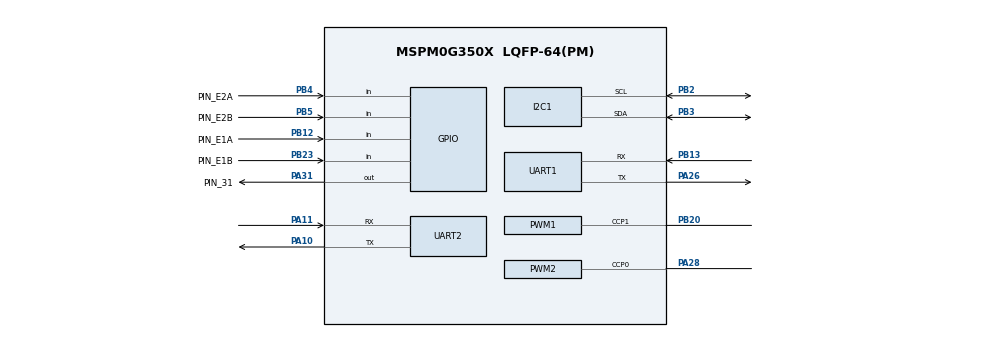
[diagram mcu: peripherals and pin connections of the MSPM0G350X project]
/**
 * @cliArgs --device "MSPM0G350X" --part "Default" --package "LQFP-64(PM)" --product "mspm0_sdk@2.10.00.04"
 * @versions {"tool":"1.27.1+4634"}
 */

/**
 * Import the modules used in this configuration.
 */
const ADC12         = scripting.addModule("/ti/driverlib/ADC12", {}, false);
const ADC121        = ADC12.addInstance();
const Board         = scripting.addModule("/ti/driverlib/Board");
const GPIO          = scripting.addModule("/ti/driverlib/GPIO", {}, false);
const GPIO1         = GPIO.addInstance();
const GPIO2         = GPIO.addInstance();
const GPIO3         = GPIO.addInstance();
const GPIO4         = GPIO.addInstance();
const GPIO5         = GPIO.addInstance();
const GPIO6         = GPIO.addInstance();
const GPIO7         = GPIO.addInstance();
const GPIO8         = GPIO.addInstance();
const GPIO9         = GPIO.addInstance();
const GPIO10        = GPIO.addInstance();
const GPIO11        = GPIO.addInstance();
const GPIO12        = GPIO.addInstance();
const GPIO13        = GPIO.addInstance();
const I2C           = scripting.addModule("/ti/driverlib/I2C", {}, false);
const I2C1          = I2C.addInstance();
const MATHACL       = scripting.addModule("/ti/driverlib/MATHACL");
const PWM           = scripting.addModule("/ti/driverlib/PWM", {}, false);
const PWM1          = PWM.addInstance();
const PWM2          = PWM.addInstance();
const SYSCTL        = scripting.addModule("/ti/driverlib/SYSCTL");
const UART          = scripting.addModule("/ti/driverlib/UART", {}, false);
const UART1         = UART.addInstance();
const UART2         = UART.addInstance();
const ProjectConfig = scripting.addModule("/ti/project_config/ProjectConfig");

/**
 * Write custom configuration values to the imported modules.
 */
const divider9       = system.clockTree["UDIV"];
divider9.divideValue = 2;

const gate7  = system.clockTree["MFCLKGATE"];
gate7.enable = true;

const mux4       = system.clockTree["EXHFMUX"];
mux4.inputSelect = "EXHFMUX_XTAL";

const mux5       = system.clockTree["EXLFMUX"];
mux5.inputSelect = "EXLFMUX_XTAL";

const mux8       = system.clockTree["HSCLKMUX"];
mux8.inputSelect = "HSCLKMUX_SYSPLL2X";

const mux12       = system.clockTree["SYSPLLMUX"];
mux12.inputSelect = "zSYSPLLMUX_HFCLK";

const pinFunction4     = system.clockTree["HFXT"];
pinFunction4.enable    = true;
pinFunction4.inputFreq = 40;

const pinFunction6     = system.clockTree["LFXT"];
pinFunction6.enable    = true;
pinFunction6.inputFreq = 32.768;

ADC121.$name                      = "ADC12_0";
ADC121.configureDMA               = true;
ADC121.enabledDMATriggers         = ["DL_ADC12_DMA_MEM0_RESULT_LOADED"];
ADC121.sampCnt                    = 1;
ADC121.repeatMode                 = true;
ADC121.sampleTime0                = "0.5 ms";
ADC121.peripheral.adcPin0.$assign = "PA27";
ADC121.adcPin0Config.$name        = "ti_driverlib_gpio_GPIOPinGeneric4";
ADC121.DMA_CHANNEL.$name          = "DMA_CH0";
ADC121.DMA_CHANNEL.transferMode   = "FULL_CH_REPEAT_SINGLE";
ADC121.DMA_CHANNEL.srcLength      = "HALF_WORD";
ADC121.DMA_CHANNEL.dstLength      = "HALF_WORD";


GPIO1.port                          = "PORTB";
GPIO1.$name                         = "LED1";
GPIO1.associatedPins[0].$name       = "PIN_22";
GPIO1.associatedPins[0].assignedPin = "22";

GPIO2.$name                         = "AD0";
GPIO2.port                          = "PORTA";
GPIO2.associatedPins[0].$name       = "PIN_31";
GPIO2.associatedPins[0].assignedPin = "31";
GPIO2.associatedPins[0].pin.$assign = "PA31";

GPIO3.$name                   = "AD1";
GPIO3.port                    = "PORTA";
GPIO3.associatedPins[0].$name = "PIN_12";

GPIO4.$name                         = "AD2";
GPIO4.port                          = "PORTB";
GPIO4.associatedPins[0].$name       = "PIN_8";
GPIO4.associatedPins[0].assignedPin = "8";

GPIO5.$name                         = "EN";
GPIO5.port                          = "PORTB";
GPIO5.associatedPins[0].$name       = "PIN_27";
GPIO5.associatedPins[0].assignedPin = "27";

GPIO6.$name                         = "AIN1";
GPIO6.port                          = "PORTA";
GPIO6.associatedPins[0].$name       = "PIN_13";
GPIO6.associatedPins[0].assignedPin = "13";

GPIO7.$name                         = "AIN2";
GPIO7.port                          = "PORTB";
GPIO7.associatedPins[0].$name       = "PIN_26";
GPIO7.associatedPins[0].assignedPin = "26";

GPIO8.$name                         = "BIN1";
GPIO8.port                          = "PORTB";
GPIO8.associatedPins[0].$name       = "PIN_9";
GPIO8.associatedPins[0].assignedPin = "9";

GPIO9.$name                         = "BIN2";
GPIO9.port                          = "PORTB";
GPIO9.associatedPins[0].$name       = "PIN_7";
GPIO9.associatedPins[0].assignedPin = "7";

GPIO10.$name                              = "E1A";
GPIO10.port                               = "PORTB";
GPIO10.associatedPins[0].$name            = "PIN_E1A";
GPIO10.associatedPins[0].direction        = "INPUT";
GPIO10.associatedPins[0].internalResistor = "PULL_UP";
GPIO10.associatedPins[0].interruptEn      = true;
GPIO10.associatedPins[0].polarity         = "RISE_FALL";
GPIO10.associatedPins[0].pin.$assign      = "PB12";

GPIO11.$name                              = "E1B";
GPIO11.port                               = "PORTB";
GPIO11.associatedPins[0].$name            = "PIN_E1B";
GPIO11.associatedPins[0].direction        = "INPUT";
GPIO11.associatedPins[0].internalResistor = "PULL_UP";
GPIO11.associatedPins[0].interruptEn      = true;
GPIO11.associatedPins[0].polarity         = "RISE_FALL";
GPIO11.associatedPins[0].pin.$assign      = "PB23";

GPIO12.$name                              = "E2A";
GPIO12.port                               = "PORTB";
GPIO12.associatedPins[0].$name            = "PIN_E2A";
GPIO12.associatedPins[0].direction        = "INPUT";
GPIO12.associatedPins[0].internalResistor = "PULL_UP";
GPIO12.associatedPins[0].interruptEn      = true;
GPIO12.associatedPins[0].polarity         = "RISE_FALL";
GPIO12.associatedPins[0].pin.$assign      = "PB4";

GPIO13.$name                              = "E2B";
GPIO13.port                               = "PORTB";
GPIO13.associatedPins[0].$name            = "PIN_E2B";
GPIO13.associatedPins[0].direction        = "INPUT";
GPIO13.associatedPins[0].internalResistor = "PULL_UP";
GPIO13.associatedPins[0].interruptEn      = true;
GPIO13.associatedPins[0].polarity         = "RISE_FALL";
GPIO13.associatedPins[0].pin.$assign      = "PB5";

I2C1.$name                             = "OLED";
I2C1.basicEnableController             = true;
I2C1.basicControllerBusSpeed           = 400000;
I2C1.peripheral.sdaPin.$assign         = "PB3";
I2C1.peripheral.sclPin.$assign         = "PB2";
I2C1.sdaPinConfig.hideOutputInversion  = scripting.forceWrite(false);
I2C1.sdaPinConfig.onlyInternalResistor = scripting.forceWrite(false);
I2C1.sdaPinConfig.passedPeripheralType = scripting.forceWrite("Digital");
I2C1.sdaPinConfig.$name                = "ti_driverlib_gpio_GPIOPinGeneric5";
I2C1.sclPinConfig.hideOutputInversion  = scripting.forceWrite(false);
I2C1.sclPinConfig.onlyInternalResistor = scripting.forceWrite(false);
I2C1.sclPinConfig.passedPeripheralType = scripting.forceWrite("Digital");
I2C1.sclPinConfig.$name                = "ti_driverlib_gpio_GPIOPinGeneric6";

PWM1.pwmMode                                 = "EDGE_ALIGN_UP";
PWM1.ccIndexCmpl                             = [0];
PWM1.$name                                   = "PWMB";
PWM1.PWM_CHANNEL_0.$name                     = "ti_driverlib_pwm_PWMTimerCC0";
PWM1.PWM_CHANNEL_1.$name                     = "ti_driverlib_pwm_PWMTimerCC1";
PWM1.ccp0PinConfig.direction                 = scripting.forceWrite("OUTPUT");
PWM1.ccp0PinConfig.hideOutputInversion       = scripting.forceWrite(false);
PWM1.ccp0PinConfig.onlyInternalResistor      = scripting.forceWrite(false);
PWM1.ccp0PinConfig.passedPeripheralType      = scripting.forceWrite("Digital");
PWM1.ccp0PinConfig.$name                     = "ti_driverlib_gpio_GPIOPinGeneric7";
PWM1.ccp1PinConfig.direction                 = scripting.forceWrite("OUTPUT");
PWM1.ccp1PinConfig.hideOutputInversion       = scripting.forceWrite(false);
PWM1.ccp1PinConfig.onlyInternalResistor      = scripting.forceWrite(false);
PWM1.ccp1PinConfig.passedPeripheralType      = scripting.forceWrite("Digital");
PWM1.ccp1PinConfig.$name                     = "ti_driverlib_gpio_GPIOPinGeneric8";
PWM1.peripheral.ccp1Pin.$assign              = "PB20";
PWM1.ccp0Pin_cmplConfig.direction            = scripting.forceWrite("OUTPUT");
PWM1.ccp0Pin_cmplConfig.hideOutputInversion  = scripting.forceWrite(false);
PWM1.ccp0Pin_cmplConfig.onlyInternalResistor = scripting.forceWrite(false);
PWM1.ccp0Pin_cmplConfig.passedPeripheralType = scripting.forceWrite("Digital");
PWM1.ccp0Pin_cmplConfig.$name                = "ti_driverlib_gpio_GPIOPinGeneric11";

PWM2.$name                              = "PWMA";
PWM2.peripheral.ccp0Pin.$assign         = "PA28";
PWM2.PWM_CHANNEL_0.$name                = "ti_driverlib_pwm_PWMTimerCC2";
PWM2.PWM_CHANNEL_1.$name                = "ti_driverlib_pwm_PWMTimerCC3";
PWM2.ccp0PinConfig.direction            = scripting.forceWrite("OUTPUT");
PWM2.ccp0PinConfig.hideOutputInversion  = scripting.forceWrite(false);
PWM2.ccp0PinConfig.onlyInternalResistor = scripting.forceWrite(false);
PWM2.ccp0PinConfig.passedPeripheralType = scripting.forceWrite("Digital");
PWM2.ccp0PinConfig.$name                = "ti_driverlib_gpio_GPIOPinGeneric9";
PWM2.ccp1PinConfig.direction            = scripting.forceWrite("OUTPUT");
PWM2.ccp1PinConfig.hideOutputInversion  = scripting.forceWrite(false);
PWM2.ccp1PinConfig.onlyInternalResistor = scripting.forceWrite(false);
PWM2.ccp1PinConfig.passedPeripheralType = scripting.forceWrite("Digital");
PWM2.ccp1PinConfig.$name                = "ti_driverlib_gpio_GPIOPinGeneric10";

SYSCTL.powerSysInterrupts = ["FLASH_SEC"];
SYSCTL.clockTreeEn        = true;

UART1.$name                            = "IMU";
UART1.enabledInterrupts                = ["RX"];
UART1.targetBaudRate                   = 115200;
UART1.uartClkDiv                       = "2";
UART1.peripheral.rxPin.$assign         = "PB13";
UART1.peripheral.txPin.$assign         = "PA26";
UART1.txPinConfig.direction            = scripting.forceWrite("OUTPUT");
UART1.txPinConfig.hideOutputInversion  = scripting.forceWrite(false);
UART1.txPinConfig.onlyInternalResistor = scripting.forceWrite(false);
UART1.txPinConfig.passedPeripheralType = scripting.forceWrite("Digital");
UART1.txPinConfig.$name                = "ti_driverlib_gpio_GPIOPinGeneric0";
UART1.rxPinConfig.hideOutputInversion  = scripting.forceWrite(false);
UART1.rxPinConfig.onlyInternalResistor = scripting.forceWrite(false);
UART1.rxPinConfig.passedPeripheralType = scripting.forceWrite("Digital");
UART1.rxPinConfig.$name                = "ti_driverlib_gpio_GPIOPinGeneric1";

UART2.$name                            = "PRINT";
UART2.targetBaudRate                   = 115200;
UART2.peripheral.rxPin.$assign         = "PA11";
UART2.peripheral.txPin.$assign         = "PA10";
UART2.txPinConfig.direction            = scripting.forceWrite("OUTPUT");
UART2.txPinConfig.hideOutputInversion  = scripting.forceWrite(false);
UART2.txPinConfig.onlyInternalResistor = scripting.forceWrite(false);
UART2.txPinConfig.passedPeripheralType = scripting.forceWrite("Digital");
UART2.txPinConfig.$name                = "ti_driverlib_gpio_GPIOPinGeneric2";
UART2.rxPinConfig.hideOutputInversion  = scripting.forceWrite(false);
UART2.rxPinConfig.onlyInternalResistor = scripting.forceWrite(false);
UART2.rxPinConfig.passedPeripheralType = scripting.forceWrite("Digital");
UART2.rxPinConfig.$name                = "ti_driverlib_gpio_GPIOPinGeneric3";

ProjectConfig.genLibDrivers = true;
ProjectConfig.genLinker     = false;
ProjectConfig.genStartup    = false;
ProjectConfig.genOpts       = false;
ProjectConfig.genLibs       = false;
scripting.suppress("All four File Generation options must be enabled in order to guarantee Device Migration support\\. If an option is disabled, the user must manually configure that setting on its own file\\.", ProjectConfig);

/**
 * Pinmux solution for unlocked pins/peripherals. This ensures that minor changes to the automatic solver in a future
 * version of the tool will not impact the pinmux you originally saw.  These lines can be completely deleted in order to
 * re-solve from scratch.
 */
pinFunction4.peripheral.$suggestSolution           = "SYSCTL";
pinFunction4.peripheral.hfxInPin.$suggestSolution  = "PA5";
pinFunction4.peripheral.hfxOutPin.$suggestSolution = "PA6";
pinFunction6.peripheral.$suggestSolution           = "SYSCTL";
pinFunction6.peripheral.lfxInPin.$suggestSolution  = "PA3";
pinFunction6.peripheral.lfxOutPin.$suggestSolution = "PA4";
ADC121.peripheral.$suggestSolution                 = "ADC0";
ADC121.DMA_CHANNEL.peripheral.$suggestSolution     = "DMA_CH0";
Board.peripheral.$suggestSolution                  = "DEBUGSS";
Board.peripheral.swclkPin.$suggestSolution         = "PA20";
Board.peripheral.swdioPin.$suggestSolution         = "PA19";
GPIO1.associatedPins[0].pin.$suggestSolution       = "PB22";
GPIO3.associatedPins[0].pin.$suggestSolution       = "PA12";
GPIO4.associatedPins[0].pin.$suggestSolution       = "PB8";
GPIO5.associatedPins[0].pin.$suggestSolution       = "PB27";
GPIO6.associatedPins[0].pin.$suggestSolution       = "PA13";
GPIO7.associatedPins[0].pin.$suggestSolution       = "PB26";
GPIO8.associatedPins[0].pin.$suggestSolution       = "PB9";
GPIO9.associatedPins[0].pin.$suggestSolution       = "PB7";
I2C1.peripheral.$suggestSolution                   = "I2C1";
PWM1.peripheral.$suggestSolution                   = "TIMA0";
PWM1.peripheral.ccp0Pin.$suggestSolution           = "PA0";
PWM1.peripheral.ccp0Pin_cmpl.$suggestSolution      = "PA22";
PWM2.peripheral.$suggestSolution                   = "TIMA1";
PWM2.peripheral.ccp1Pin.$suggestSolution           = "PA16";
UART1.peripheral.$suggestSolution                  = "UART3";
UART2.peripheral.$suggestSolution                  = "UART0";
